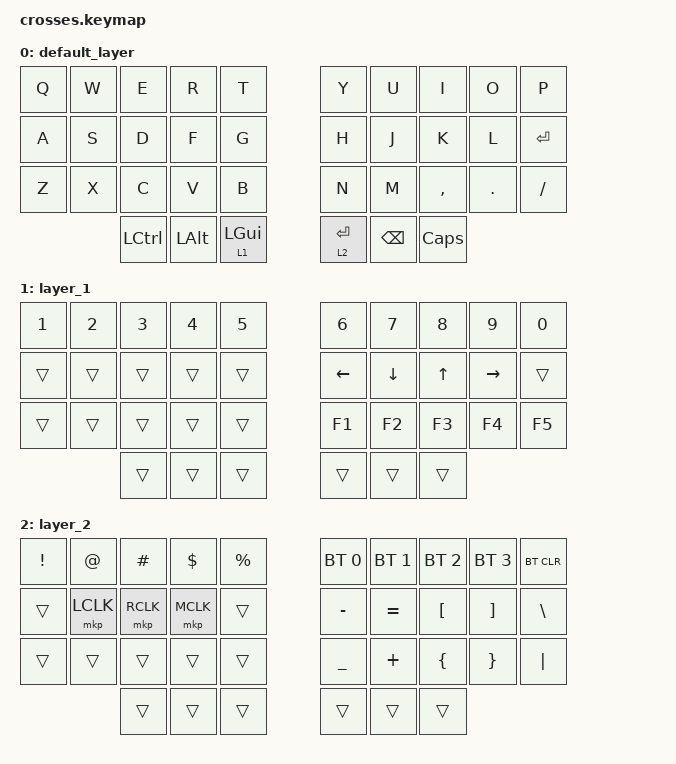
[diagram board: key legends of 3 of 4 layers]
#include <behaviors.dtsi>
#include <dt-bindings/zmk/keys.h>
#include <dt-bindings/zmk/bt.h>
#include <dt-bindings/zmk/mouse.h>

/ {
    keymap {
        compatible = "zmk,keymap";

        // LAYER 0: Mac Base
        default_layer {
            bindings = <
    &kp Q      &kp W      &kp E       &kp R       &kp T           &kp Y       &kp U       &kp I       &kp O       &kp P
    &kp A      &kp S      &kp D       &kp F       &kp G           &kp H       &kp J       &kp K       &kp L       &kp RET
    &kp Z      &kp X      &kp C       &kp V       &kp B           &kp N       &kp M       &kp COMMA   &kp DOT     &kp SLASH
    &kp LCTRL  &kp LALT   &lt 1 LGUI                              &lt 2 ENTER &kp BSPC    &kp CAPS
            >;
        };

        // LAYER 1: Numbers & Arrows
        layer_1 {
            bindings = <
    &kp N1     &kp N2     &kp N3      &kp N4      &kp N5          &kp N6      &kp N7      &kp N8      &kp N9      &kp N0
    &trans     &trans     &trans      &trans      &trans          &kp LEFT    &kp DOWN    &kp UP      &kp RIGHT   &trans
    &trans     &trans     &trans      &trans      &trans          &kp F1      &kp F2      &kp F3      &kp F4      &kp F5
    &trans     &trans     &trans                                  &trans      &trans      &trans
            >;
        };

        // LAYER 2: BT Clear & Select (Focused on Right Side)
        layer_2 {
            bindings = <
    &kp EXCL   &kp AT     &kp HASH    &kp DLLR    &kp PRCNT       &bt BT_SEL 0 &bt BT_SEL 1 &bt BT_SEL 2 &bt BT_SEL 3 &bt BT_CLR
    &trans     &mkp LCLK  &mkp RCLK   &mkp MCLK   &trans          &kp MINUS    &kp EQUAL    &kp LBKT     &kp RBKT     &kp BSLH
    &trans     &trans     &trans      &trans      &trans          &kp UNDER    &kp PLUS     &kp LBRC     &kp RBRC     &kp PIPE
    &trans     &trans     &trans                                  &trans       &trans       &trans
            >;
        };
    };
};

/ {
    behaviors {
        // トラックボールの動作を定義
        mmv: mouse_move {
            compatible = "zmk,behavior-mouse-move";
            #binding-cells = <1>;
        };
        mwh: mouse_wheel {
            compatible = "zmk,behavior-mouse-wheel";
            #binding-cells = <1>;
        };
    };

    keymap {
        // 必要に応じてマウスキーを設定
        mouse_layer {
            bindings = <
                &mmv LEFT &mmv RIGHT &mmv UP &mmv DOWN
                &mwh UP &mwh DOWN
            >;
        };
    };
};
